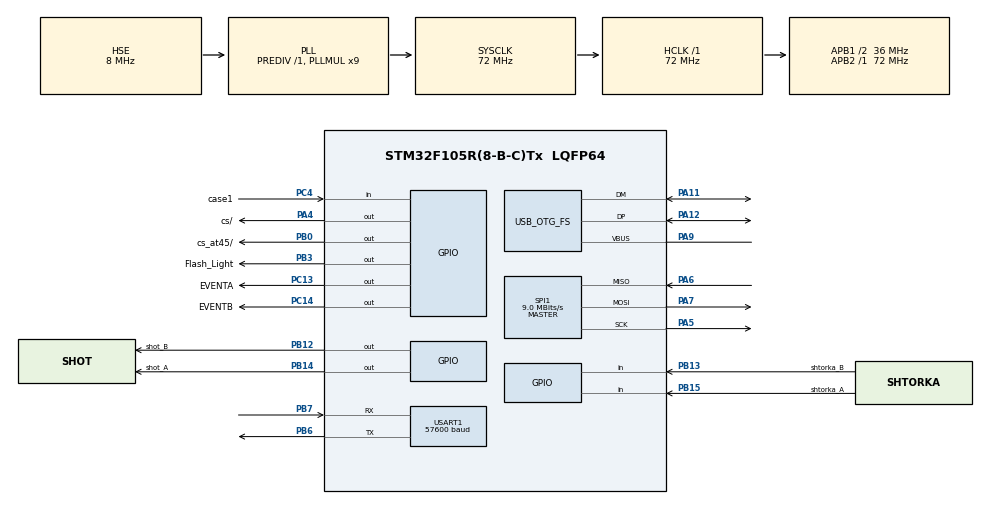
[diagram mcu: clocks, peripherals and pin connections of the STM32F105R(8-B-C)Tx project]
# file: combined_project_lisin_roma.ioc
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Mcu.Family=STM32F1
Mcu.Name=STM32F105R(8-B-C)Tx
Mcu.Package=LQFP64
NVIC.OTG_FS_IRQn=true\:0\:0\:false\:false\:true\:false\:true\:true
NVIC.PriorityGroup=NVIC_PRIORITYGROUP_4
NVIC.USART1_IRQn=true\:0\:0\:false\:false\:true\:true\:true\:true
PA11.Mode=Device_Only
PA11.Signal=USB_OTG_FS_DM
PA12.Mode=Device_Only
PA12.Signal=USB_OTG_FS_DP
PA13.Mode=Serial_Wire
PA13.Signal=SYS_JTMS-SWDIO
PA14.Mode=Serial_Wire
PA14.Signal=SYS_JTCK-SWCLK
PA4.GPIO_Label=cs/
PA4.GPIO_PuPd=GPIO_NOPULL
PA4.GPIO_Speed=GPIO_SPEED_FREQ_HIGH
PA4.PinState=GPIO_PIN_SET
PA4.Signal=GPIO_Output
PA5.Mode=Full_Duplex_Master
PA5.Signal=SPI1_SCK
PA6.Mode=Full_Duplex_Master
PA6.Signal=SPI1_MISO
PA7.Mode=Full_Duplex_Master
PA7.Signal=SPI1_MOSI
PA9.Mode=Activate_VBUS
PA9.Signal=USB_OTG_FS_VBUS
PB0.GPIO_Label=cs_at45/
PB0.GPIO_Speed=GPIO_SPEED_FREQ_HIGH
PB0.PinState=GPIO_PIN_SET
PB0.Signal=GPIO_Output
PB12.GPIO_Label=shot_B
PB12.GPIO_Speed=GPIO_SPEED_FREQ_HIGH
PB12.PinState=GPIO_PIN_SET
PB12.Signal=GPIO_Output
PB13.GPIO_Label=shtorka_B
PB13.GPIO_PuPd=GPIO_PULLUP
PB13.Signal=GPIO_Input
PB14.GPIO_Label=shot_A
PB14.GPIO_Speed=GPIO_SPEED_FREQ_HIGH
PB14.PinState=GPIO_PIN_SET
PB14.Signal=GPIO_Output
PB15.GPIO_Label=shtorka_A
PB15.GPIO_PuPd=GPIO_PULLUP
PB15.Signal=GPIO_Input
PB3.GPIO_Label=Flash_Light
PB3.Signal=GPIO_Output
PB6.Mode=Asynchronous
PB6.Signal=USART1_TX
PB7.Mode=Asynchronous
PB7.Signal=USART1_RX
PC13-TAMPER-RTC.GPIO_Label=EVENTA
PC13-TAMPER-RTC.GPIO_Speed=GPIO_SPEED_FREQ_HIGH
PC13-TAMPER-RTC.PinState=GPIO_PIN_SET
PC13-TAMPER-RTC.Signal=GPIO_Output
PC14-OSC32_IN.GPIO_Label=EVENTB
PC14-OSC32_IN.GPIO_Speed=GPIO_SPEED_FREQ_HIGH
PC14-OSC32_IN.PinState=GPIO_PIN_SET
PC14-OSC32_IN.Signal=GPIO_Output
PC4.GPIO_Label=case1
PC4.GPIO_PuPd=GPIO_PULLUP
PC4.Signal=GPIO_Input
PD0-OSC_IN.Mode=HSE-External-Oscillator
PD0-OSC_IN.Signal=RCC_OSC_IN
PD1-OSC_OUT.Mode=HSE-External-Oscillator
PD1-OSC_OUT.Signal=RCC_OSC_OUT
ProjectManager.HeapSize=0x2000
ProjectManager.StackSize=0x2000
ProjectManager.TargetToolchain=MDK-ARM V5
RCC.AHBFreq_Value=72000000
RCC.APB1CLKDivider=RCC_HCLK_DIV2
RCC.APB1Freq_Value=36000000
RCC.APB1TimFreq_Value=72000000
RCC.APB2Freq_Value=72000000
RCC.APB2TimFreq_Value=72000000
RCC.HCLKFreq_Value=72000000
RCC.PLLMUL=RCC_PLL_MUL9
RCC.PLLSourceVirtual=RCC_PLLSOURCE_HSE
RCC.Prediv2=RCC_HSE_PREDIV2_DIV2
RCC.SYSCLKFreq_VALUE=72000000
RCC.SYSCLKSource=RCC_SYSCLKSOURCE_PLLCLK
RCC.USBFreq_Value=48000000
SPI1.BaudRatePrescaler=SPI_BAUDRATEPRESCALER_8
SPI1.CalculateBaudRate=9.0 MBits/s
SPI1.Direction=SPI_DIRECTION_2LINES
SPI1.Mode=SPI_MODE_MASTER
SPI1.VirtualType=VM_MASTER
USART1.BaudRate=57600
USART1.VirtualMode=VM_ASYNC
USB_DEVICE.CLASS_NAME_FS=MSC
USB_DEVICE.VirtualMode=Msc
USB_DEVICE.VirtualModeFS=Msc_FS
USB_OTG_FS.VirtualMode=Device_Only
VP_USB_DEVICE_VS_USB_DEVICE_MSC_FS.Mode=MSC_FS
board=custom

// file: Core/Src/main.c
/* USER CODE BEGIN Header */
/**
  ******************************************************************************
  * @file           : main.c
  * @brief          : Main program body
  ******************************************************************************
  * @attention
  *
  * <h2><center>&copy; Copyright (c) 2023 STMicroelectronics.
  * All rights reserved.</center></h2>
  *
  * This software component is licensed by ST under Ultimate Liberty license
  * SLA0044, the "License"; You may not use this file except in compliance with
  * the License. You may obtain a copy of the License at:
  *                             www.st.com/SLA0044
  *
  ******************************************************************************
  */
/* USER CODE END Header */
#include "main.h"
#include "spi.h"
#include "usart.h"
#include "usb_device.h"
#include "gpio.h"
#include "filesys.h"
#include "camera.h"
#include "stdio.h"
#include "ringfs.h"
#include "StorageMode.h"

void SystemClock_Config(void);

int main(void)
{

  /* MCU Configuration--------------------------------------------------------*/

  /* Reset of all peripherals, Initializes the Flash interface and the Systick. */
  HAL_Init();

  /* Configure the system clock */
  SystemClock_Config();

  /* Initialize all configured peripherals */
  MX_GPIO_Init();
  //MX_SPI1_Init();
  //MX_USART1_UART_Init();
	HAL_Delay(10);
  MX_SPI1_Init();
	HAL_Delay(10);
  MX_USART1_UART_Init();
	HAL_Delay(10);

	//extern struct ringfs ring_structure;

	ringfs_init(&ring_structure, &flash, LOG_ENTRY_VERSION, magic_size_of_entry);
  /* USER CODE BEGIN 2 */
	uint8_t main_test_buffer[] = "This is a test string of a size 95 and I have to fill the rest of it with some senseless garbage";
	uint8_t second_test_buffer[]="ALso is another test string of a size 95, I hope...or not really...ok lets write more garbagezlo";
	uint8_t third_test_buffer[] ="Tyger Tyger, burning bright,In the forests of the nightWhat immortal hand or eye,could frame thy";
  /* USER CODE END 2 */

	//ascam_emfat_scan(&ring_structure, entries, entry_name_array);

  /* Infinite loop */
  /* USER CODE BEGIN WHILE */

	generate_fname(1);
	initfilesystem();
	//initfile();

	//savedata(2, 0, 0, 0, 0, 0, 0, 0, 0, 0, 0, 0, 0, 0, 0, 0);
	//ringfs_append(&ring_structure, transformed_buffer_to_uint8_t, 96, 8);
	//ringfs_append(&ring_structure,  second_test_buffer, sizeof(main_test_buffer)-1, 123);
	//ringfs_append(&ring_structure,  second_test_buffer, sizeof(main_test_buffer)-1, 123);

	//for(int i = 0; i < 103; i++){
	//savedata(2, 0, 0, 0, 0, 0, 0, 0, 0, 0, 0, 0, 0, 0, 0, 0);
  //}
	//at45dbxx_erase_chip();

	//closefile();
	ascam_emfat_scan(&ring_structure, entries, entry_name_array);
	emfat_init(&emfat, "Ascam", entries);
	EMFAT_USB_DEVICE_Init();
  while (1)
  {

	receive_cmd();
    /* USER CODE END WHILE */

  }
}

void SystemClock_Config(void)
{
  RCC_OscInitTypeDef RCC_OscInitStruct = {0};
  RCC_ClkInitTypeDef RCC_ClkInitStruct = {0};
  RCC_PeriphCLKInitTypeDef PeriphClkInit = {0};

  /** Initializes the RCC Oscillators according to the specified parameters
  * in the RCC_OscInitTypeDef structure.
  */
  RCC_OscInitStruct.OscillatorType = RCC_OSCILLATORTYPE_HSE;
  RCC_OscInitStruct.HSEState = RCC_HSE_ON;
  RCC_OscInitStruct.HSEPredivValue = RCC_HSE_PREDIV_DIV1;
  RCC_OscInitStruct.HSIState = RCC_HSI_ON;
  RCC_OscInitStruct.Prediv1Source = RCC_PREDIV1_SOURCE_HSE;
  RCC_OscInitStruct.PLL.PLLState = RCC_PLL_ON;
  RCC_OscInitStruct.PLL.PLLSource = RCC_PLLSOURCE_HSE;
  RCC_OscInitStruct.PLL.PLLMUL = RCC_PLL_MUL9;
  RCC_OscInitStruct.PLL2.PLL2State = RCC_PLL_NONE;
  if (HAL_RCC_OscConfig(&RCC_OscInitStruct) != HAL_OK)
  {
    Error_Handler();
  }
  /** Initializes the CPU, AHB and APB buses clocks
  */
  RCC_ClkInitStruct.ClockType = RCC_CLOCKTYPE_HCLK|RCC_CLOCKTYPE_SYSCLK
                              |RCC_CLOCKTYPE_PCLK1|RCC_CLOCKTYPE_PCLK2;
  RCC_ClkInitStruct.SYSCLKSource = RCC_SYSCLKSOURCE_PLLCLK;
  RCC_ClkInitStruct.AHBCLKDivider = RCC_SYSCLK_DIV1;
  RCC_ClkInitStruct.APB1CLKDivider = RCC_HCLK_DIV2;
  RCC_ClkInitStruct.APB2CLKDivider = RCC_HCLK_DIV1;

  if (HAL_RCC_ClockConfig(&RCC_ClkInitStruct, FLASH_LATENCY_2) != HAL_OK)
  {
    Error_Handler();
  }
  PeriphClkInit.PeriphClockSelection = RCC_PERIPHCLK_USB;
  PeriphClkInit.UsbClockSelection = RCC_USBCLKSOURCE_PLL_DIV3;
  if (HAL_RCCEx_PeriphCLKConfig(&PeriphClkInit) != HAL_OK)
  {
    Error_Handler();
  }
  /** Configure the Systick interrupt time
  */
  __HAL_RCC_PLLI2S_ENABLE();
}

void Error_Handler(void)
{
  __disable_irq();
  while (1)
  {
  }
}

/************************ (C) COPYRIGHT STMicroelectronics *****END OF FILE****/
